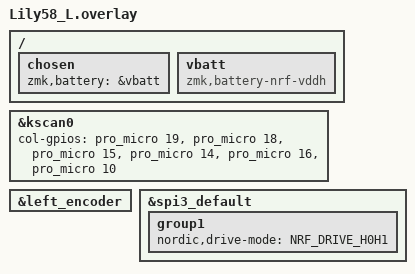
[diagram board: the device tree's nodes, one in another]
/*
 * Copyright (c) 2020 Pete Johanson
 *
 * SPDX-License-Identifier: MIT
 */

#include "Lily58.dtsi"

&kscan0 {
    col-gpios
        = <&pro_micro 19 GPIO_ACTIVE_HIGH>
        , <&pro_micro 18 GPIO_ACTIVE_HIGH>
        , <&pro_micro 15 GPIO_ACTIVE_HIGH>
        , <&pro_micro 14 GPIO_ACTIVE_HIGH>
        , <&pro_micro 16 GPIO_ACTIVE_HIGH>
        , <&pro_micro 10 GPIO_ACTIVE_HIGH>
        ;
};

&left_encoder {
    status = "okay";
};

// RGB 数据脚改高推力（仅左手），3.3V 推 SK6812 时边沿更陡、高电平更足
&spi3_default {
    group1 {
        nordic,drive-mode = <NRF_DRIVE_H0H1>;
    };
};
/ {
    chosen {
      zmk,battery = &vbatt;
    };

    vbatt: vbatt {
        compatible = "zmk,battery-nrf-vddh";
    };
};
